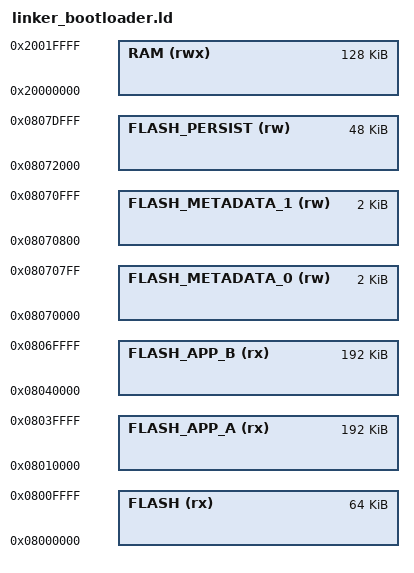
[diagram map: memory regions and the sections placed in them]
/* STM32G4 internal-flash template. Adjust FLASH/RAM sizes for the exact part. */
MEMORY
{
  FLASH (rx) : ORIGIN = 0x08000000, LENGTH = 64K
  FLASH_APP_A (rx) : ORIGIN = 0x08010000, LENGTH = 192K
  FLASH_APP_B (rx) : ORIGIN = 0x08040000, LENGTH = 192K
  FLASH_METADATA_0 (rw) : ORIGIN = 0x08070000, LENGTH = 2K
  FLASH_METADATA_1 (rw) : ORIGIN = 0x08070800, LENGTH = 2K
  FLASH_PERSIST (rw) : ORIGIN = 0x08072000, LENGTH = 48K
  RAM (rwx)  : ORIGIN = 0x20000000, LENGTH = 128K
}
